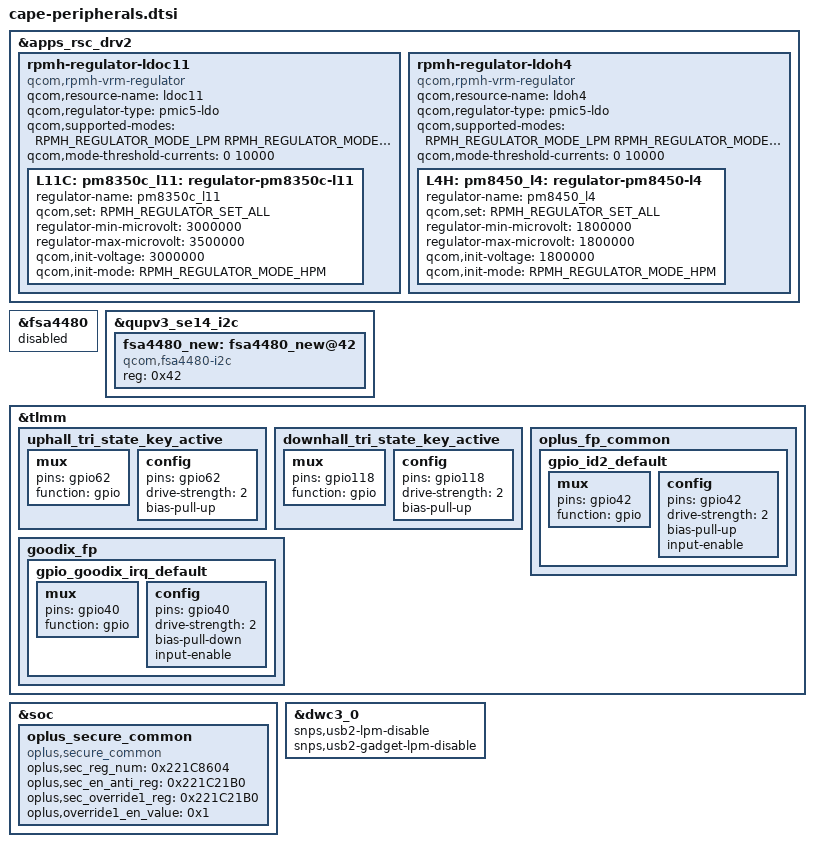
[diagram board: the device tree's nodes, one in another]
#include <dt-bindings/regulator/qcom,rpmh-regulator-levels.h>

&apps_rsc_drv2 {

	rpmh-regulator-ldoc11 {
		compatible = "qcom,rpmh-vrm-regulator";
		qcom,resource-name = "ldoc11";
		qcom,regulator-type = "pmic5-ldo";
		qcom,supported-modes =
			<RPMH_REGULATOR_MODE_LPM
			 RPMH_REGULATOR_MODE_HPM>;
		qcom,mode-threshold-currents = <0 10000>;
		L11C: pm8350c_l11: regulator-pm8350c-l11 {
			regulator-name = "pm8350c_l11";
			qcom,set = <RPMH_REGULATOR_SET_ALL>;
			regulator-min-microvolt = <3000000>;
			regulator-max-microvolt = <3500000>;
			qcom,init-voltage = <3000000>;
			qcom,init-mode = <RPMH_REGULATOR_MODE_HPM>;
		};
	};

	rpmh-regulator-ldoh4 {
		compatible = "qcom,rpmh-vrm-regulator";
		qcom,resource-name = "ldoh4";
		qcom,regulator-type = "pmic5-ldo";
		qcom,supported-modes =
			<RPMH_REGULATOR_MODE_LPM
			 RPMH_REGULATOR_MODE_HPM>;
		qcom,mode-threshold-currents = <0 10000>;
		L4H: pm8450_l4: regulator-pm8450-l4 {
			regulator-name = "pm8450_l4";
			qcom,set = <RPMH_REGULATOR_SET_ALL>;
			regulator-min-microvolt = <1800000>;
			regulator-max-microvolt = <1800000>;
			qcom,init-voltage = <1800000>;
			qcom,init-mode = <RPMH_REGULATOR_MODE_HPM>;
		};
	};
};

&fsa4480 {
	status = "disabled";
};

&qupv3_se14_i2c {
	status = "ok";
	fsa4480_new: fsa4480_new@42 {
		status = "ok";
		compatible = "qcom,fsa4480-i2c";
		reg = <0x42>;
	};
};

&tlmm {
	uphall_tri_state_key_active: uphall_tri_state_key_active {
		mux {
			pins = "gpio62";
			function = "gpio";
		};
		config {
			pins = "gpio62";
			drive-strength = <2>;
			bias-pull-up;
		};
	};

	downhall_tri_state_key_active: downhall_tri_state_key_active {
		mux {
			pins = "gpio118";
			function = "gpio";
		};
		config {
			pins = "gpio118";
			drive-strength = <2>;
			bias-pull-up;
		};
	};

	oplus_fp_common{
		gpio_id2_default: gpio_id2_default {
			mux {
				pins = "gpio42";
				function = "gpio";
			};
			config {
				pins = "gpio42";
				drive-strength = <2>;
				bias-pull-up;
				input-enable;
			};
		};
	};
	goodix_fp{
		gpio_goodix_irq_default: gpio_goodix_irq_default {
			mux {
				pins = "gpio40";
				function = "gpio";
			};
			config {
				pins = "gpio40";
				drive-strength = <2>;
				bias-pull-down;
				input-enable;
			};
		};
	};

};

&soc {
	oplus_secure_common {
		compatible = "oplus,secure_common";
		oplus,sec_reg_num = <0x221C8604>;
		oplus,sec_en_anti_reg = <0x221C21B0>;
		oplus,sec_override1_reg = <0x221C21B0>;
		oplus,override1_en_value = <0x1>;
	};
};

&dwc3_0 {
	snps,usb2-lpm-disable;
	snps,usb2-gadget-lpm-disable;
};
